AUTOSAR XML (schema 4-3-0)
standard types defined: UINT8, UINT16, UINT32, UINT64, SINT8, SINT16, SINT32, FLOAT32, FLOAT64
package /Pkg_DegManager_B/ComponentTypes
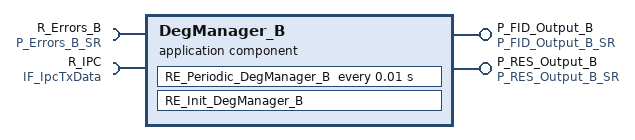
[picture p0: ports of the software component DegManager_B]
  application sw component type DegManager_B
    provide port P_FID_Output_B: nonqueued-sender-com-spec=data-element=FID_B, provided-interface=P_FID_Output_B_SR
    provide port P_RES_Output_B: nonqueued-sender-com-spec=data-element=RES_B, provided-interface=P_RES_Output_B_SR
    require port R_Errors_B: nonqueued-receiver-com-spec{data-element=Errors_B, init-value=constant-reference=init_Errors_B}, required-interface=P_Errors_B_SR
    require port R_IPC: client-com-spec=IPC_Write_v, required-interface=IF_IpcTxData
    behavior DegManager_B_InternalBehavior: handle-termination-and-restart=NO-SUPPORT
      timing event TMT_RE_Periodic_DegManager_B: start-on-event=RE_Periodic_DegManager_B, period=0.01
      init event InitEvent: start-on-event=RE_Init_DegManager_B
      port-api-options:
        enable-take-address=false, indirect-api=false, port=P_FID_Output_B
        enable-take-address=false, indirect-api=false, port=P_RES_Output_B
        enable-take-address=false, indirect-api=false, port=R_Errors_B
        enable-take-address=false, indirect-api=false, port=R_IPC
      runnable RE_Periodic_DegManager_B  # Periodic Runnable of Satellite
        data-receive-point-by-arguments:
          access REC_R_Errors_B_Errors_B: accessed-variable=R_Errors_B.Errors_B
        data-send-points:
          access SEND_P_FID_Output_B_FID_B: accessed-variable=P_FID_Output_B.FID_B
          access SEND_P_RES_Output_B_RES_B: accessed-variable=P_RES_Output_B.RES_B
        sync call SC_R_IPC_IPC_Write_v: operation=R_IPC.IPC_Write_v, timeout=0
      runnable RE_Init_DegManager_B  # Init Runnable
  swc implementation DegManager_B_Implementation: programming-language=C, vendor-id=0, behavior=DegManager_B_InternalBehavior
    code-descriptors:
      code Default: artifact-descriptors=autosar-engineering-object={short-label=Default, category=SWSRC}
package /Pkg_DegManager_B/Constant
  constant specification init_FID_B: value-spec=[0, 0]
  constant specification init_RES_B: value-spec=[0]
package /Pkg_DegManager_B/ImplementationDataTypes
  5 x impl type, all with type-emitter=RTE:
    BOOL: implementation-data-type=boolean
    ErrorMgr_ErrorField: implementation-data-type=uint8
    ErrorListArr_B: category=ARRAY
      element Elem_uint32: array-size=35, array-size-semantics=FIXED-SIZE, implementation-data-type=uint32
    FIDOutputArr_B: category=ARRAY
      element Elem_uint32: array-size=2, array-size-semantics=FIXED-SIZE, implementation-data-type=uint32
    RESOutputArr_B: category=ARRAY
      element Elem_uint32: array-size=1, array-size-semantics=FIXED-SIZE, implementation-data-type=uint32
package /Pkg_DegManager_B/PortInterfaces
  sender receiver interface P_FID_Output_B_SR  # Output
    data FID_B: type=FIDOutputArr_B
  sender receiver interface P_RES_Output_B_SR  # Output
    data RES_B: type=RESOutputArr_B
